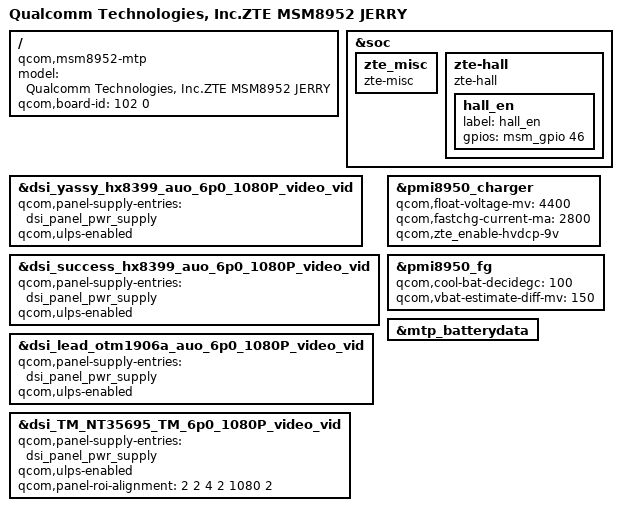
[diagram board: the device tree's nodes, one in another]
/*
 * Copyright (c) 2015, The Linux Foundation. All rights reserved.
 *
 * This program is free software; you can redistribute it and/or modify
 * it under the terms of the GNU General Public License version 2 and
 * only version 2 as published by the Free Software Foundation.
 *
 * This program is distributed in the hope that it will be useful,
 * but WITHOUT ANY WARRANTY; without even the implied warranty of
 * MERCHANTABILITY or FITNESS FOR A PARTICULAR PURPOSE.  See the
 * GNU General Public License for more details.
 */

/dts-v1/;

#include "msm8952-mtp.dtsi"
#include "zte-msm8952-jerry.dtsi"

#include "dsi-panel-zte-success-hx8399-auo-6p0-1080p-video.dtsi"
#include "dsi-panel-zte-tm-nt35695-tm-6p0-1080p-video.dtsi"
#include "dsi-panel-zte-lead_otm1906a_auo_6p0_1080p_cmd.dtsi"
#include "dsi-panel-zte-YASSY-HX8399-auo-6p0-1080p-video.dtsi"

/ {
	model = "Qualcomm Technologies, Inc.ZTE MSM8952 JERRY";
	compatible = "qcom,msm8952-mtp", "qcom,msm8952", "qcom,mtp";
	qcom,board-id= <102 0>;
};
&soc {
        zte_misc {
                compatible = "zte-misc";
        };
        zte-hall {
                compatible = "zte-hall";
                hall_en{	                      
                        label = "hall_en";	
                        gpios = <&msm_gpio 46 0x0>;
            	};	
        };      
};
&dsi_yassy_hx8399_auo_6p0_1080P_video_vid {
	qcom,panel-supply-entries = <&dsi_panel_pwr_supply>;
	qcom,ulps-enabled;
};
&dsi_success_hx8399_auo_6p0_1080P_video_vid {
	qcom,panel-supply-entries = <&dsi_panel_pwr_supply>;
	qcom,ulps-enabled;
};
&dsi_lead_otm1906a_auo_6p0_1080P_video_vid {
	qcom,panel-supply-entries = <&dsi_panel_pwr_supply>;
	qcom,ulps-enabled;
};
&dsi_TM_NT35695_TM_6p0_1080P_video_vid {
	qcom,panel-supply-entries = <&dsi_panel_pwr_supply>;
	qcom,ulps-enabled;
	qcom,panel-roi-alignment = <2 2 4 2 1080 2>;
};
&pmi8950_charger {
	qcom,float-voltage-mv = <4400>;
	qcom,fastchg-current-ma = <2800>;
	qcom,zte_enable-hvdcp-9v;
};
&pmi8950_fg{
	qcom,cool-bat-decidegc = <100>;
	qcom,vbat-estimate-diff-mv = <150>;
};
&mtp_batterydata {
		#include "ZTE_P895A16_3400mAh.dtsi"
};

